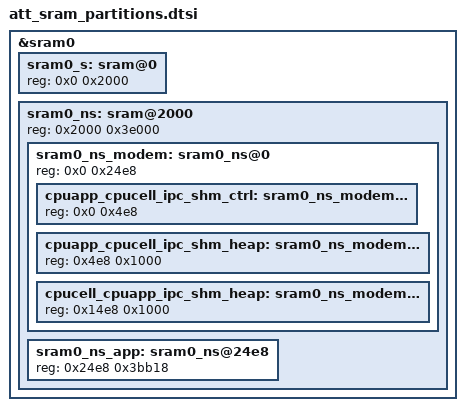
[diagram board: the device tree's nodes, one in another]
/*
 * Copyright (c) 2026 Nordic Semiconductor ASA
 *
 * SPDX-License-Identifier: LicenseRef-Nordic-5-Clause
 *
 * SRAM layout (256 KiB total):
 *
 *    0x2000_0000  Secure RAM                    (    8 KiB)
 *    0x2000_2000  Non-secure RAM                (  248 KiB)
 *      0x2000_2000  Modem shared area           (  9416 B)
 *        0x2000_2000  control                   (  1256 B)
 *        0x2000_24e8  app -> cell               (  4096 B)
 *        0x2000_34e8  cell -> app               (  4096 B)
 *      0x2000_44e8  Application RAM             (~238.8 KiB)
 */

/delete-node/ &sram0_s;
/delete-node/ &sram0_ns;

&sram0 {
	sram0_s: sram@0 {
		reg = <0x0 0x2000>;
	};

	sram0_ns: sram@2000 {
		reg = <0x2000 0x3e000>;
		#address-cells = <1>;
		#size-cells = <1>;
		ranges = <0x0 0x2000 0x3e000>;

		/* Must be in first 128 kB of RAM. */
		sram0_ns_modem: sram0_ns@0 {
			reg = <0x0 0x24e8>;
			#address-cells = <1>;
			#size-cells = <1>;
			ranges = <0x0 0x0 0x24e8>;

			cpuapp_cpucell_ipc_shm_ctrl: sram0_ns_modem@0 {
				/* NRF_MODEM_SHMEM_CTRL_SIZE for nRF91 cellular */
				reg = <0x0 0x4e8>;
			};

			cpuapp_cpucell_ipc_shm_heap: sram0_ns_modem@4e8 {
				/* CONFIG_NRF_MODEM_LIB_SHMEM_TX_SIZE = 4096 */
				reg = <0x4e8 0x1000>;
			};

			cpucell_cpuapp_ipc_shm_heap: sram0_ns_modem@14e8 {
				/* CONFIG_NRF_MODEM_LIB_SHMEM_RX_SIZE = 4096 */
				reg = <0x14e8 0x1000>;
			};
		};

		sram0_ns_app: sram0_ns@24e8 {
			reg = <0x24e8 0x3bb18>;
		};
	};
};
